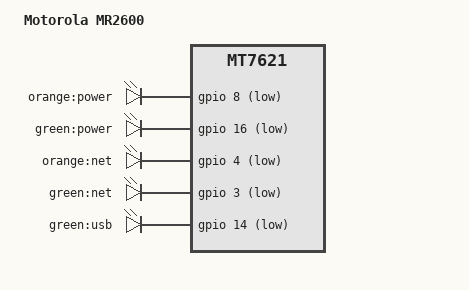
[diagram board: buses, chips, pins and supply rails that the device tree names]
// SPDX-License-Identifier: GPL-2.0-or-later OR MIT

#include "mt7621_dlink_dir-8xx-a1.dtsi"

/ {
	compatible = "motorola,motorola-mr2600", "mediatek,mt7621-soc";
	model = "Motorola MR2600";

	aliases {
		led-boot = &led_power_orange;
		led-failsafe = &led_power_green;
		led-running = &led_power_green;
		led-upgrade = &led_net_orange;
	};

	leds {
		compatible = "gpio-leds";

		led_power_orange: power_orange {
			label = "orange:power";
			gpios = <&gpio 8 GPIO_ACTIVE_LOW>;
		};

		led_power_green: power_green {
			label = "green:power";
			gpios = <&gpio 16 GPIO_ACTIVE_LOW>;
		};

		led_net_orange: net_orange {
			label = "orange:net";
			gpios = <&gpio 4 GPIO_ACTIVE_LOW>;
		};

		net_green {
			label = "green:net";
			gpios = <&gpio 3 GPIO_ACTIVE_LOW>;
		};

		usb {
			label = "green:usb";
			gpios = <&gpio 14 GPIO_ACTIVE_LOW>;
			trigger-sources = <&xhci_ehci_port1>, <&ehci_port2>;
			linux,default-trigger = "usbport";
		};
	};
};
